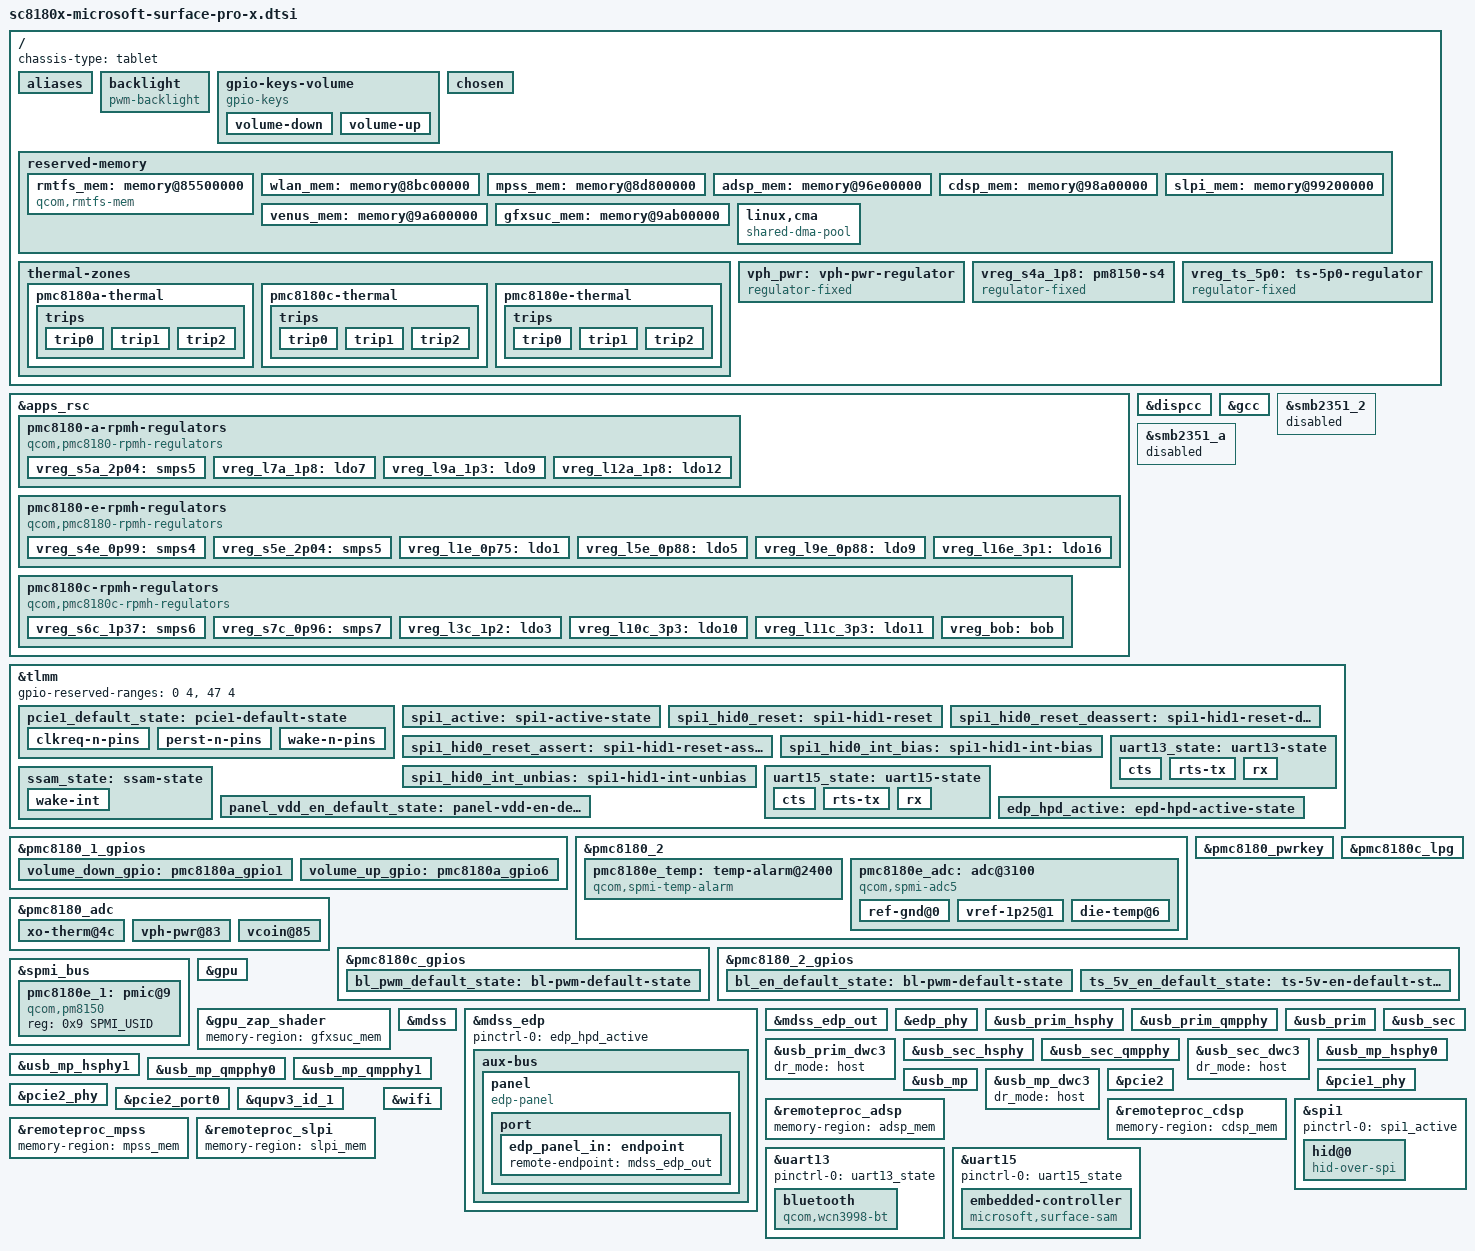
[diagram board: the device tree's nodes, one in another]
// SPDX-License-Identifier: BSD-3-Clause
/*
 * Based on:
 % - sc8180x-primus.dts
 % - sc8180x-lenovo-flex-5g.dts
 */

/dts-v1/;

#include <dt-bindings/gpio/gpio.h>
#include <dt-bindings/input/linux-event-codes.h>
#include <dt-bindings/interrupt-controller/irq.h>
#include <dt-bindings/regulator/qcom,rpmh-regulator.h>
#include <dt-bindings/spmi/spmi.h>
#include <dt-bindings/iio/qcom,spmi-vadc.h>
#include "sc8180x.dtsi"
#include "sc8180x-pmics.dtsi"

/delete-node/ &gpu_mem;

/ {
	chassis-type = "tablet";

	aliases {
		serial0 = &uart13;
		serial1 = &uart15;
	};

	backlight: backlight {
		compatible = "pwm-backlight";

		pwms = <&pmc8180c_lpg 4 5000000>;
		enable-gpios = <&pmc8180_2_gpios 1 GPIO_ACTIVE_HIGH>;

		pinctrl-names = "default";
		pinctrl-0 = <&bl_pwm_default_state &bl_en_default_state>;
	};

	gpio-keys-volume {
		compatible = "gpio-keys";
		label = "Volume Buttons";
		autorepeat;

		pinctrl-names = "default";
		pinctrl-0 = <&volume_down_gpio &volume_up_gpio>;

		volume-down {
			label = "Volume Down";
			gpios = <&pmc8180_1_gpios 1 GPIO_ACTIVE_LOW>;
			linux,code = <KEY_VOLUMEDOWN>;
		};

		volume-up {
			label = "Volume Up";
			gpios = <&pmc8180_1_gpios 6 GPIO_ACTIVE_LOW>;
			linux,code = <KEY_VOLUMEUP>;
		};
	};

	chosen {
	};

	reserved-memory {
		rmtfs_mem: memory@85500000 {
			compatible = "qcom,rmtfs-mem";
			reg = <0x0 0x85500000 0x0 0x200000>;
			no-map;

			qcom,client-id = <1>;
			qcom,vmid = <15>;
		};

		wlan_mem: memory@8bc00000 {
			reg = <0x0 0x8bc00000 0x0 0x180000>;
			no-map;
		};

		mpss_mem: memory@8d800000 { /* non-relocatable */
			reg = <0x0 0x8d800000 0x0 0x9600000>;
			no-map;
		};

		adsp_mem: memory@96e00000 {
			reg = <0x0 0x96e00000 0x0 0x1c00000>;
			no-map;
		};

		cdsp_mem: memory@98a00000 {
			reg = <0x0 0x98a00000 0x0 0x800000>;
			no-map;
		};

		slpi_mem: memory@99200000 {
			reg = <0x0 0x99200000 0x0 0x1400000>;
			no-map;
		};

		venus_mem: memory@9a600000 {
			reg = <0x0 0x9a600000 0x0 0x500000>;
			no-map;
		};

		gfxsuc_mem: memory@9ab00000 {
			reg = <0x0 0x9ab00000 0x0 0x5000>;
			no-map;
		};

		linux,cma {
			compatible = "shared-dma-pool";
			size = <0x0 0x8000000>;
			reusable;
			linux,cma-default;
		};
	};

	thermal-zones {
		pmc8180a-thermal {
			polling-delay-passive = <100>;
			polling-delay = <0>;

			thermal-sensors = <&pmc8180_temp>;

			trips {
				trip0 {
					temperature = <95000>;
					hysteresis = <0>;
					type = "passive";
				};

				trip1 {
					temperature = <115000>;
					hysteresis = <0>;
					type = "hot";
				};

				trip2 {
					temperature = <145000>;
					hysteresis = <0>;
					type = "critical";
				};
			};
		};

		pmc8180c-thermal {
			polling-delay-passive = <100>;
			polling-delay = <0>;

			thermal-sensors = <&pmc8180c_temp>;

			trips {
				trip0 {
					temperature = <95000>;
					hysteresis = <0>;
					type = "passive";
				};

				trip1 {
					temperature = <115000>;
					hysteresis = <0>;
					type = "hot";
				};

				trip2 {
					temperature = <145000>;
					hysteresis = <0>;
					type = "critical";
				};
			};
		};

		pmc8180e-thermal {
			polling-delay-passive = <100>;
			polling-delay = <0>;

			thermal-sensors = <&pmc8180e_temp>;

			trips {
				trip0 {
					temperature = <95000>;
					hysteresis = <0>;
					type = "passive";
				};

				trip1 {
					temperature = <115000>;
					hysteresis = <0>;
					type = "hot";
				};

				trip2 {
					temperature = <145000>;
					hysteresis = <0>;
					type = "critical";
				};
			};
		};
	};

	vph_pwr: vph-pwr-regulator {
		compatible = "regulator-fixed";
		regulator-name = "vph_pwr";
		regulator-min-microvolt = <3700000>;
		regulator-max-microvolt = <3700000>;

		regulator-always-on;
		regulator-boot-on;
	};

	vreg_s4a_1p8: pm8150-s4 {
		compatible = "regulator-fixed";
		regulator-name = "vreg_s4a_1p8";

		regulator-min-microvolt = <1800000>;
		regulator-max-microvolt = <1800000>;

		regulator-always-on;
		regulator-boot-on;

		vin-supply = <&vph_pwr>;
	};

	vreg_ts_5p0: ts-5p0-regulator {
		compatible = "regulator-fixed";
		regulator-name = "vreg_ts_5p0";

		regulator-min-microvolt = <5000000>;
		regulator-max-microvolt = <5000000>;

		gpio = <&pmc8180_2_gpios 10 GPIO_ACTIVE_HIGH>;
		enable-active-high;

		pinctrl-names = "default";
		pinctrl-0 = <&ts_5v_en_default_state>;
	};
};

&apps_rsc {
	pmc8180-a-rpmh-regulators {
		compatible = "qcom,pmc8180-rpmh-regulators";
		qcom,pmic-id = "a";

		vdd-s1-supply = <&vph_pwr>;
		vdd-s2-supply = <&vph_pwr>;
		vdd-s3-supply = <&vph_pwr>;
		vdd-s4-supply = <&vph_pwr>;
		vdd-s5-supply = <&vph_pwr>;
		vdd-s6-supply = <&vph_pwr>;
		vdd-s7-supply = <&vph_pwr>;
		vdd-s8-supply = <&vph_pwr>;
		vdd-s9-supply = <&vph_pwr>;
		vdd-s10-supply = <&vph_pwr>;

		vdd-l1-l8-l11-supply = <&vreg_s6c_1p37>;
		vdd-l2-l10-supply = <&vreg_bob>;
		vdd-l3-l4-l5-l18-supply = <&vreg_s7c_0p96>;
		vdd-l6-l9-supply = <&vreg_s6c_1p37>;
		vdd-l7-l12-l14-l15-supply = <&vreg_s5a_2p04>;
		vdd-l13-l16-l17-supply = <&vreg_bob>;

		vreg_s5a_2p04: smps5 {
			regulator-min-microvolt = <2040000>;
			regulator-max-microvolt = <2040000>;
		};

		vreg_l7a_1p8: ldo7 {
			regulator-min-microvolt = <1800000>;
			regulator-max-microvolt = <1800000>;
			regulator-initial-mode = <RPMH_REGULATOR_MODE_HPM>;
		};

		vreg_l9a_1p3: ldo9 {
			regulator-min-microvolt = <1296000>;
			regulator-max-microvolt = <1304000>;
			regulator-initial-mode = <RPMH_REGULATOR_MODE_HPM>;
		};

		vreg_l12a_1p8: ldo12 {
			regulator-min-microvolt = <1800000>;
			regulator-max-microvolt = <1800000>;
			regulator-initial-mode = <RPMH_REGULATOR_MODE_HPM>;
		};
	};

	pmc8180-e-rpmh-regulators {
		compatible = "qcom,pmc8180-rpmh-regulators";
		qcom,pmic-id = "e";

		vdd-s1-supply = <&vph_pwr>;
		vdd-s2-supply = <&vph_pwr>;
		vdd-s3-supply = <&vph_pwr>;
		vdd-s4-supply = <&vph_pwr>;
		vdd-s5-supply = <&vph_pwr>;
		vdd-s6-supply = <&vph_pwr>;
		vdd-s7-supply = <&vph_pwr>;
		vdd-s8-supply = <&vph_pwr>;
		vdd-s9-supply = <&vph_pwr>;
		vdd-s10-supply = <&vph_pwr>;

		vdd-l1-l8-l11-supply = <&vreg_s4e_0p99>;
		vdd-l2-l10-supply = <&vreg_bob>;
		vdd-l3-l4-l5-l18-supply = <&vreg_s4e_0p99>;
		vdd-l6-l9-supply = <&vreg_s4e_0p99>;
		vdd-l7-l12-l14-l15-supply = <&vreg_s5e_2p04>;
		vdd-l13-l16-l17-supply = <&vreg_bob>;

		vreg_s4e_0p99: smps4 {
			regulator-min-microvolt = <992000>;
			regulator-max-microvolt = <992000>;
			regulator-initial-mode = <RPMH_REGULATOR_MODE_HPM>;
		};

		vreg_s5e_2p04: smps5 {
			regulator-min-microvolt = <2040000>;
			regulator-max-microvolt = <2040000>;
			regulator-initial-mode = <RPMH_REGULATOR_MODE_HPM>;
		};

		vreg_l1e_0p75: ldo1 {
			regulator-min-microvolt = <752000>;
			regulator-max-microvolt = <752000>;
			regulator-initial-mode = <RPMH_REGULATOR_MODE_HPM>;
		};

		vreg_l5e_0p88: ldo5 {
			regulator-min-microvolt = <880000>;
			regulator-max-microvolt = <880000>;
			regulator-initial-mode = <RPMH_REGULATOR_MODE_HPM>;
		};

		vreg_l9e_0p88: ldo9 {
			regulator-min-microvolt = <880000>;
			regulator-max-microvolt = <880000>;
			regulator-initial-mode = <RPMH_REGULATOR_MODE_HPM>;
		};

		vreg_l16e_3p1: ldo16 {
			regulator-min-microvolt = <3072000>;
			regulator-max-microvolt = <3072000>;
			regulator-initial-mode = <RPMH_REGULATOR_MODE_HPM>;
		};
	};

	pmc8180c-rpmh-regulators {
		compatible = "qcom,pmc8180c-rpmh-regulators";
		qcom,pmic-id = "c";

		vdd-s1-supply = <&vph_pwr>;
		vdd-s2-supply = <&vph_pwr>;
		vdd-s3-supply = <&vph_pwr>;
		vdd-s4-supply = <&vph_pwr>;
		vdd-s5-supply = <&vph_pwr>;
		vdd-s6-supply = <&vph_pwr>;
		vdd-s7-supply = <&vph_pwr>;
		vdd-s8-supply = <&vph_pwr>;

		vdd-l1-l8-supply = <&vreg_s4a_1p8>;
		vdd-l2-l3-supply = <&vreg_s6c_1p37>;
		vdd-l4-l5-l6-supply = <&vreg_bob>;
		vdd-l7-l11-supply = <&vreg_bob>;
		vdd-l9-l10-supply = <&vreg_bob>;

		vdd-bob-supply = <&vph_pwr>;
		vdd-flash-supply = <&vreg_bob>;
		vdd-rgb-supply = <&vreg_bob>;

		vreg_s6c_1p37: smps6 {
			regulator-min-microvolt = <1350000>;
			regulator-max-microvolt = <1372000>;
			regulator-initial-mode = <RPMH_REGULATOR_MODE_HPM>;
		};

		vreg_s7c_0p96: smps7 {
			regulator-min-microvolt = <960000>;
			regulator-max-microvolt = <960000>;
			regulator-initial-mode = <RPMH_REGULATOR_MODE_HPM>;
		};

		vreg_l3c_1p2: ldo3 {
			regulator-min-microvolt = <1200000>;
			regulator-max-microvolt = <1200000>;
			regulator-initial-mode = <RPMH_REGULATOR_MODE_HPM>;
		};

		vreg_l10c_3p3: ldo10 {
			regulator-min-microvolt = <3296000>;
			regulator-max-microvolt = <3312000>;
			regulator-initial-mode = <RPMH_REGULATOR_MODE_HPM>;
		};

		vreg_l11c_3p3: ldo11 {
			regulator-min-microvolt = <3296000>;
			regulator-max-microvolt = <3304000>;
			regulator-initial-mode = <RPMH_REGULATOR_MODE_HPM>;
		};

		vreg_bob: bob {
			regulator-min-microvolt = <3296000>;
			regulator-max-microvolt = <3350000>;
			regulator-initial-mode = <RPMH_REGULATOR_MODE_HPM>;
		};
	};
};

&dispcc {
	status = "okay";
};

&gcc {
	protected-clocks = <GCC_QSPI_CORE_CLK>,
			   <GCC_QSPI_CORE_CLK_SRC>,
			   <GCC_QSPI_CNOC_PERIPH_AHB_CLK>;
};

&smb2351_2 {
	status = "disabled";
};

&smb2351_a {
	status = "disabled";
};

&tlmm {
	gpio-reserved-ranges = <0 4>, <47 4>;

	pcie1_default_state: pcie1-default-state {
		clkreq-n-pins {
			pins = "gpio176";
			function = "pci_e2";
			drive-strength = <2>;
			bias-pull-up;
		};

		perst-n-pins {
			pins = "gpio102";
			function = "gpio";
			drive-strength = <2>;
			bias-disable;
		};

		wake-n-pins {
			pins = "gpio104";
			function = "gpio";
			drive-strength = <2>;
			bias-pull-up;
		};
	};

	spi1_active: spi1-active-state {
		pins = "gpio114", "gpio115", "gpio116", "gpio117";
		function = "qup1";

		drive-strength = <6>;
		bias-disable;
	};

	spi1_hid0_reset: spi1-hid1-reset {
		pins = "gpio54";
		function = "gpio";
		drive-strength = <2>;
		bias-disable;
	};

	spi1_hid0_reset_deassert: spi1-hid1-reset-deassert {
		pins = "gpio54";
		function = "gpio";
		drive-strength = <2>;
		bias-disable;
		output-high;
	};

	spi1_hid0_reset_assert: spi1-hid1-reset-assert {
		pins = "gpio54";
		function = "gpio";
		drive-strength = <2>;
		bias-disable;
		output-low;
	};

	spi1_hid0_int_bias: spi1-hid1-int-bias {
		pins = "gpio122";
		function = "gpio";

		input-enable;
		bias-pull-up;
	};

	spi1_hid0_int_unbias: spi1-hid1-int-unbias {
		pins = "gpio122";
		function = "gpio";

		input-enable;
		bias-disable;
	};

	uart13_state: uart13-state {
		cts {
			pins = "gpio43";
			function = "qup13";
			bias-pull-down;
		};

		rts-tx {
			pins = "gpio44", "gpio45";
			function = "qup13";
			drive-strength = <2>;
			bias-disable;
		};

		rx {
			pins = "gpio46";
			function = "qup13";
			bias-pull-up;
		};
	};

	uart15_state: uart15-state {
		cts {
			pins = "gpio27";
			function = "qup15";
			bias-pull-down;
		};

		rts-tx {
			pins = "gpio28", "gpio29";
			function = "qup15";
			drive-strength = <2>;
			bias-disable;
		};

		rx {
			pins = "gpio30";
			function = "qup15";
			bias-pull-up;
		};
	};

	ssam_state: ssam-state {
		wake-int {
			pins = "gpio180";
			function = "gpio";
			bias-disable;
		};
	};

	panel_vdd_en_default_state: panel-vdd-en-default-state {
		pins = "gpio130";
		function = "gpio";

		drive-strength = <2>;
		bias-disable;
		output-high;
	};

	edp_hpd_active: epd-hpd-active-state {
		pins = "gpio10";
		function = "edp_hot";
	};
};

&pmc8180_1_gpios {
	volume_down_gpio: pmc8180a_gpio1 {
		pins = "gpio1";
		function = "normal";
		input-enable;
		bias-pull-up;
		qcom,drive-strength = <0>;
	};

	volume_up_gpio: pmc8180a_gpio6 {
		pins = "gpio6";
		function = "normal";
		input-enable;
		bias-pull-up;
		qcom,drive-strength = <0>;
	};
};

&pmc8180_2 {
	pmc8180e_temp: temp-alarm@2400 {
		compatible = "qcom,spmi-temp-alarm";
		reg = <0x2400>;
		interrupts = <0x8 0x24 0x0 IRQ_TYPE_EDGE_BOTH>;
		io-channels = <&pmc8180e_adc ADC5_DIE_TEMP>;
		io-channel-names = "thermal";
		#thermal-sensor-cells = <0>;
	};

	pmc8180e_adc: adc@3100 {
		compatible = "qcom,spmi-adc5";
		reg = <0x3100>;
		#address-cells = <1>;
		#size-cells = <0>;
		#io-channel-cells = <1>;
		interrupts = <0x8 0x31 0x0 IRQ_TYPE_EDGE_RISING>;

		ref-gnd@0 {
			reg = <ADC5_REF_GND>;
			qcom,pre-scaling = <1 1>;
			label = "ref_gnd";
		};

		vref-1p25@1 {
			reg = <ADC5_1P25VREF>;
			qcom,pre-scaling = <1 1>;
			label = "vref_1p25";
		};

		die-temp@6 {
			reg = <ADC5_DIE_TEMP>;
			qcom,pre-scaling = <1 1>;
			label = "die_temp";
		};
	};
};

&pmc8180_adc {
	xo-therm@4c {
		reg = <ADC5_XO_THERM_100K_PU>;
		qcom,ratiometric;
		qcom,pre-scaling = <1 1>;
		qcom,hw-settle-time = <200>;
		label = "xo_therm";
	};

	vph-pwr@83 {
		reg = <ADC5_VPH_PWR>;
		qcom,pre-scaling = <1 3>;
		label = "vph_pwr";
	};

	vcoin@85 {
		reg = <ADC5_VCOIN>;
		qcom,pre-scaling = <1 3>;
		label = "vcoin";
	};
};

&pmc8180_pwrkey {
	status = "okay";
};

&pmc8180c_gpios {
	bl_pwm_default_state: bl-pwm-default-state {
		pins = "gpio10";
		function = "func1";
	};
};

&pmc8180c_lpg {
	status = "okay";
};

&pmc8180_2_gpios {
	bl_en_default_state: bl-pwm-default-state {
		pins = "gpio1";
		function = "normal";
	};

	ts_5v_en_default_state: ts-5v-en-default-state {
		pins = "gpio10";
		function = "normal";
	};
};

&spmi_bus {
	pmc8180e_1: pmic@9 {
		compatible = "qcom,pm8150", "qcom,spmi-pmic";
		reg = <0x9 SPMI_USID>;
		#address-cells = <1>;
		#size-cells = <0>;
	};
};

&gpu {
	status = "okay";
};

&gpu_zap_shader {
	memory-region = <&gfxsuc_mem>;
};

&mdss {
	status = "okay";
};

&mdss_edp {
	pinctrl-0 = <&edp_hpd_active>;
	pinctrl-names = "default";

	status = "okay";

	aux-bus {
		panel {
			compatible = "edp-panel";
			enable-gpios = <&tlmm 130 GPIO_ACTIVE_HIGH>;
			no-hpd;

			pinctrl-0 = <&panel_vdd_en_default_state>;
			pinctrl-names = "default";

			backlight = <&backlight>;

			port {
				edp_panel_in: endpoint {
					remote-endpoint = <&mdss_edp_out>;
				};
			};
		};
	};
};

&mdss_edp_out {
	data-lanes = <0 1 2 3>;
	remote-endpoint = <&edp_panel_in>;
};

&edp_phy {
	vdda-pll-supply = <&vreg_l5e_0p88>;
	vdda-phy-supply = <&vreg_l3c_1p2>;
};

&usb_prim_hsphy {
	vdda-pll-supply = <&vreg_l9e_0p88>;
	vdda18-supply = <&vreg_l12a_1p8>;
	vdda33-supply = <&vreg_l16e_3p1>;

	status = "okay";
};

&usb_prim_qmpphy {
	vdda-phy-supply = <&vreg_l3c_1p2>;
	vdda-pll-supply = <&vreg_l9e_0p88>;

	orientation-switch;

	status = "okay";
};

&usb_prim {
	status = "okay";
};

&usb_prim_dwc3 {
	dr_mode = "host";
};

&usb_sec_hsphy {
	vdda-pll-supply = <&vreg_l9e_0p88>;
	vdda18-supply = <&vreg_l12a_1p8>;
	vdda33-supply = <&vreg_l16e_3p1>;

	status = "okay";
};

&usb_sec_qmpphy {
	vdda-phy-supply = <&vreg_l3c_1p2>;
	vdda-pll-supply = <&vreg_l9e_0p88>;

	orientation-switch;

	status = "okay";
};

&usb_sec {
	status = "okay";
};

&usb_sec_dwc3 {
	dr_mode = "host";
};

&usb_mp_hsphy0 {
	vdda-pll-supply = <&vreg_l9e_0p88>;
	vdda18-supply = <&vreg_l12a_1p8>;
	vdda33-supply = <&vreg_l16e_3p1>;

	status = "okay";
};

&usb_mp_hsphy1 {
	vdda-pll-supply = <&vreg_l9e_0p88>;
	vdda18-supply = <&vreg_l12a_1p8>;
	vdda33-supply = <&vreg_l16e_3p1>;

	status = "okay";
};

&usb_mp_qmpphy0 {
	vdda-phy-supply = <&vreg_l3c_1p2>;
	vdda-pll-supply = <&vreg_l9e_0p88>;

	status = "okay";
};

&usb_mp_qmpphy1 {
	vdda-phy-supply = <&vreg_l3c_1p2>;
	vdda-pll-supply = <&vreg_l9e_0p88>;

	status = "okay";
};

&usb_mp {
	status = "okay";
};

&usb_mp_dwc3 {
	dr_mode = "host";
};

&pcie2 {
	// XXX: pcie1 and pcie2 are multi'd together, for now use just one
	num-lanes = <2>;

	pinctrl-0 = <&pcie1_default_state>;
	pinctrl-names = "default";

	// HACK: Remove "global" interrupt
	interrupts = <GIC_SPI 672 IRQ_TYPE_LEVEL_HIGH>,
		     <GIC_SPI 671 IRQ_TYPE_LEVEL_HIGH>,
		     <GIC_SPI 670 IRQ_TYPE_LEVEL_HIGH>,
		     <GIC_SPI 669 IRQ_TYPE_LEVEL_HIGH>,
		     <GIC_SPI 668 IRQ_TYPE_LEVEL_HIGH>,
		     <GIC_SPI 667 IRQ_TYPE_LEVEL_HIGH>,
		     <GIC_SPI 666 IRQ_TYPE_LEVEL_HIGH>,
		     <GIC_SPI 665 IRQ_TYPE_LEVEL_HIGH>;
	interrupt-names = "msi0",
			  "msi1",
			  "msi2",
			  "msi3",
			  "msi4",
			  "msi5",
			  "msi6",
			  "msi7";

	status = "okay";
};

&pcie1_phy {
	vdda-phy-supply = <&vreg_l5e_0p88>;
	vdda-pll-supply = <&vreg_l3c_1p2>;

	status = "okay";
};

&pcie2_phy {
	vdda-phy-supply = <&vreg_l5e_0p88>;
	vdda-pll-supply = <&vreg_l3c_1p2>;

	status = "okay";
};

&pcie2_port0 {
	reset-gpios = <&tlmm 102 GPIO_ACTIVE_LOW>;
	wake-gpios = <&tlmm 104 GPIO_ACTIVE_LOW>;
};

&qupv3_id_1 {
	status = "okay";
};

&remoteproc_adsp {
	memory-region = <&adsp_mem>;
};

&remoteproc_cdsp {
	memory-region = <&cdsp_mem>;
};

&remoteproc_mpss {
	memory-region = <&mpss_mem>;
};

&remoteproc_slpi {
	memory-region = <&slpi_mem>;
};

&spi1 {
	pinctrl-names = "default";
	pinctrl-0 = <&spi1_active>;

	status = "okay";

	hid@0 {
		compatible = "hid-over-spi";

		reg = <0>;
		spi-max-frequency = <25000000>;
		// spi-max-frequency = <12500000>;

		interrupts-extended = <&tlmm 122 IRQ_TYPE_EDGE_FALLING>;

		vdd-supply = <&vreg_ts_5p0>;

		// OLD DRV
		pinctrl-0 = <&spi1_hid0_reset_deassert &spi1_hid0_int_bias>;
		pinctrl-1 = <&spi1_hid0_reset_assert &spi1_hid0_int_unbias>;
		pinctrl-2 = <&spi1_hid0_reset_assert &spi1_hid0_int_bias>;
		pinctrl-names = "active", "sleep", "reset";
		hid-descr-addr = <1>;

		// NEW DRV
		// pinctrl-0 = <&spi1_hid0_reset &spi1_hid0_int_bias>;
		// pinctrl-1 = <&spi1_hid0_reset &spi1_hid0_int_unbias>;
		// pinctrl-2 = <&spi1_hid0_reset &spi1_hid0_int_bias>;
		// reset-gpios = <&tlmm 54 GPIO_ACTIVE_LOW>;
		// input-report-header-address = <0x1000>;
		// input-report-body-address = <0x1004>;
		// output-report-address = <0x2000>;
		// read-opcode = <0x0b>;
		// write-opcode = <0x02>;
		// hid-over-spi-flags = <0x0000>;
	};
};

&uart13 {
	pinctrl-0 = <&uart13_state>;
	pinctrl-names = "default";

	status = "okay";

	bluetooth {
		compatible = "qcom,wcn3998-bt";

		vddio-supply = <&vreg_s4a_1p8>;
		vddxo-supply = <&vreg_l7a_1p8>;
		vddrf-supply = <&vreg_l9a_1p3>;
		vddch0-supply = <&vreg_l11c_3p3>;

		max-speed = <3200000>;
	};
};

&uart15 {
	pinctrl-0 = <&uart15_state>;
	pinctrl-names = "default";

	status = "okay";

	embedded-controller {
		compatible = "microsoft,surface-sam";

		interrupts-extended = <&tlmm 180 IRQ_TYPE_EDGE_RISING>;

		current-speed = <4000000>;

		pinctrl-0 = <&ssam_state>;
		pinctrl-names = "default";
	};
};

&wifi {
	memory-region = <&wlan_mem>;

	vdd-0.8-cx-mx-supply = <&vreg_l1e_0p75>;
	vdd-1.8-xo-supply = <&vreg_l7a_1p8>;
	vdd-1.3-rfa-supply = <&vreg_l9a_1p3>;
	vdd-3.3-ch0-supply = <&vreg_l11c_3p3>;
	vdd-3.3-ch1-supply = <&vreg_l10c_3p3>;

	status = "okay";
};
